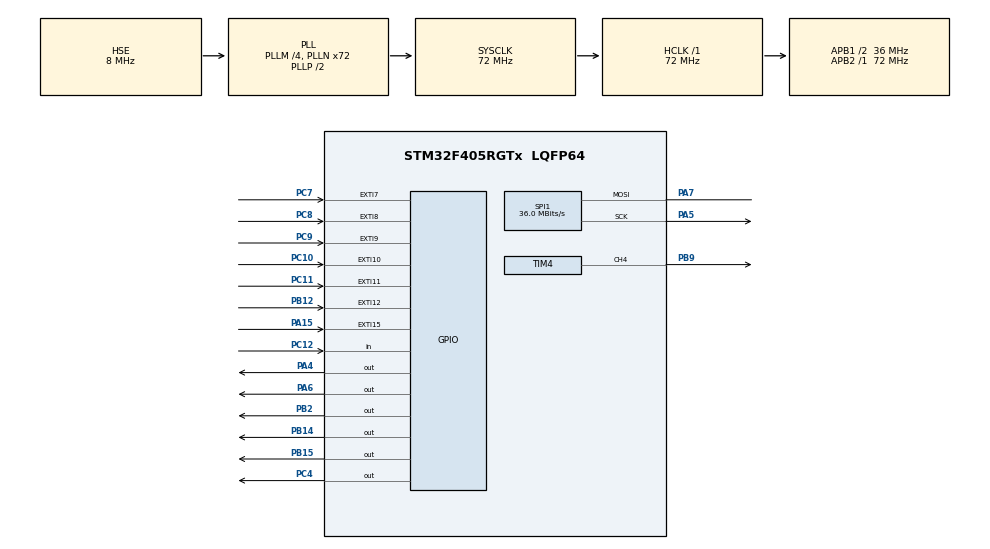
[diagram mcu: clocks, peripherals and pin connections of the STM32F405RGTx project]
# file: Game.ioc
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Dma.Request0=TIM4_UP
Dma.TIM4_UP.0.Direction=DMA_MEMORY_TO_PERIPH
Dma.TIM4_UP.0.FIFOMode=DMA_FIFOMODE_DISABLE
Dma.TIM4_UP.0.Instance=DMA1_Stream6
Dma.TIM4_UP.0.MemDataAlignment=DMA_MDATAALIGN_HALFWORD
Dma.TIM4_UP.0.MemInc=DMA_MINC_ENABLE
Dma.TIM4_UP.0.Mode=DMA_NORMAL
Dma.TIM4_UP.0.PeriphDataAlignment=DMA_PDATAALIGN_HALFWORD
Dma.TIM4_UP.0.PeriphInc=DMA_PINC_DISABLE
Dma.TIM4_UP.0.Priority=DMA_PRIORITY_LOW
Mcu.Family=STM32F4
Mcu.Name=STM32F405RGTx
Mcu.Package=LQFP64
NVIC.DMA1_Stream6_IRQn=true\:0\:0\:false\:false\:true\:false\:true
NVIC.EXTI15_10_IRQn=true\:0\:0\:false\:false\:true\:true\:true
NVIC.EXTI9_5_IRQn=true\:0\:0\:false\:false\:true\:true\:true
NVIC.HASH_RNG_IRQn=true\:0\:0\:false\:false\:true\:true\:true
NVIC.PriorityGroup=NVIC_PRIORITYGROUP_4
PA13.Mode=Serial_Wire
PA13.Signal=SYS_JTMS-SWDIO
PA14.Mode=Serial_Wire
PA14.Signal=SYS_JTCK-SWCLK
PA15.GPIO_ModeDefaultEXTI=GPIO_MODE_IT_RISING_FALLING
PA15.GPIO_PuPd=GPIO_PULLUP
PA15.Signal=GPXTI15
PA4.GPIO_PuPd=GPIO_PULLDOWN
PA4.PinState=GPIO_PIN_RESET
PA4.Signal=GPIO_Output
PA5.Mode=Simplex_Bidirectional_Master
PA5.Signal=SPI1_SCK
PA6.GPIO_PuPd=GPIO_PULLDOWN
PA6.Signal=GPIO_Output
PA7.Mode=Simplex_Bidirectional_Master
PA7.Signal=SPI1_MOSI
PB12.GPIO_PuPd=GPIO_PULLUP
PB12.Signal=GPXTI12
PB14.GPIO_PuPd=GPIO_PULLUP
PB14.Signal=GPIO_Output
PB15.GPIO_PuPd=GPIO_PULLUP
PB15.Signal=GPIO_Output
PB2.GPIO_PuPd=GPIO_PULLDOWN
PB2.Signal=GPIO_Output
PB9.Signal=S_TIM4_CH4
PC10.GPIO_ModeDefaultEXTI=GPIO_MODE_IT_RISING_FALLING
PC10.GPIO_PuPd=GPIO_PULLUP
PC10.Signal=GPXTI10
PC11.GPIO_ModeDefaultEXTI=GPIO_MODE_IT_RISING_FALLING
PC11.GPIO_PuPd=GPIO_PULLUP
PC11.Signal=GPXTI11
PC12.GPIO_PuPd=GPIO_PULLUP
PC12.Signal=GPIO_Input
PC4.GPIO_PuPd=GPIO_PULLDOWN
PC4.Signal=GPIO_Output
PC7.GPIO_ModeDefaultEXTI=GPIO_MODE_IT_RISING_FALLING
PC7.GPIO_PuPd=GPIO_PULLUP
PC7.Signal=GPXTI7
PC8.GPIO_ModeDefaultEXTI=GPIO_MODE_IT_RISING_FALLING
PC8.GPIO_PuPd=GPIO_PULLUP
PC8.Signal=GPXTI8
PC9.GPIO_ModeDefaultEXTI=GPIO_MODE_IT_RISING_FALLING
PC9.GPIO_PuPd=GPIO_PULLUP
PC9.Signal=GPXTI9
PH0-OSC_IN.Mode=HSE-External-Oscillator
PH0-OSC_IN.Signal=RCC_OSC_IN
PH1-OSC_OUT.Mode=HSE-External-Oscillator
PH1-OSC_OUT.Signal=RCC_OSC_OUT
ProjectManager.HeapSize=0x200
ProjectManager.StackSize=0x400
ProjectManager.TargetToolchain=STM32CubeIDE
RCC.48MHZClocksFreq_Value=36000000
RCC.AHBFreq_Value=72000000
RCC.APB1CLKDivider=RCC_HCLK_DIV2
RCC.APB1Freq_Value=36000000
RCC.APB1TimFreq_Value=72000000
RCC.APB2Freq_Value=72000000
RCC.APB2TimFreq_Value=72000000
RCC.CortexFreq_Value=72000000
RCC.HCLKFreq_Value=72000000
RCC.HSE_VALUE=8000000
RCC.HSI_VALUE=16000000
RCC.LSE_VALUE=32768
RCC.PLLM=4
RCC.PLLN=72
RCC.PLLSourceVirtual=RCC_PLLSOURCE_HSE
RCC.SYSCLKFreq_VALUE=72000000
RCC.SYSCLKSource=RCC_SYSCLKSOURCE_PLLCLK
RCC.VCOOutputFreq_Value=144000000
SH.S_TIM4_CH4.0=TIM4_CH4,PWM Generation4 CH4
SPI1.BaudRatePrescaler=SPI_BAUDRATEPRESCALER_2
SPI1.CalculateBaudRate=36.0 MBits/s
SPI1.Direction=SPI_DIRECTION_1LINE
SPI1.Mode=SPI_MODE_MASTER
SPI1.VirtualType=VM_MASTER
TIM4.AutoReloadPreload=TIM_AUTORELOAD_PRELOAD_DISABLE
TIM4.Channel-PWM\ Generation4\ CH4=TIM_CHANNEL_4
TIM4.Period=60000
TIM4.Prescaler=72-1
VP_RNG_VS_RNG.Mode=RNG_Activate
VP_TIM4_VS_ClockSourceINT.Mode=Internal
board=custom

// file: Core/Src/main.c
/* USER CODE BEGIN Header */
/**
  ******************************************************************************
  * @file           : main.c
  * @brief          : Main program body
  ******************************************************************************
  * @attention
  *
  * <h2><center>&copy; Copyright (c) 2022 STMicroelectronics.
  * All rights reserved.</center></h2>
  *
  * This software component is licensed by ST under BSD 3-Clause license,
  * the "License"; You may not use this file except in compliance with the
  * License. You may obtain a copy of the License at:
  *                        opensource.org/licenses/BSD-3-Clause
  *
  ******************************************************************************
  */
/* USER CODE END Header */
#include "main.h"
#include "dma.h"
#include "rng.h"
#include "spi.h"
#include "tim.h"
#include "gpio.h"

/* USER CODE BEGIN Includes */
#include "ssd1306.h"
#include "button.h"
#include "MicroMenu.h"
//#include "menu.h"
/* USER CODE END Includes */

/* USER CODE BEGIN PV */
//#include "Game_1.h"
/* USER CODE END PV */

void SystemClock_Config(void);

/* USER CODE BEGIN 0 */

/*** DUMY CODE ***/

/*** END DUMY CODE ***/

/* USER CODE END 0 */

int main(void)
{

  /* MCU Configuration--------------------------------------------------------*/

  /* Reset of all peripherals, Initializes the Flash interface and the Systick. */
  HAL_Init();

  /* Configure the system clock */
  SystemClock_Config();

  /* Initialize all configured peripherals */
  MX_GPIO_Init();
  MX_DMA_Init();
  MX_SPI1_Init();
  MX_RNG_Init();
  MX_TIM4_Init();
  /* USER CODE BEGIN 2 */
  //uint8_t a=0;
  //uint32_t osc = HAL_RCC_GetSysClockFreq();
  ssd1306_Init();
  HAL_TIM_PWM_Start(&htim4, TIM_CHANNEL_4);

	/* Set up the default menu text write callback, and navigate to an absolute menu item entry. */
	//Menu_SetGenericWriteCallback(Generic_Write);
	//Menu_Navigate(&Menu_1);

  /* USER CODE END 2 */

  /* Infinite loop */
  /* USER CODE BEGIN WHILE */
  while (1)
  {
	 Menu_General();

	//updateGame();
    //play_melody();

/*
	if (button_struct.btn_B == PRESSED_LONG){
		//ssd1306_Fill(Black);
		ssd1306_DrawRectangle(10, 40 ,SSD1306_WIDTH-1 - 9,SSD1306_HEIGHT-1 - 40,White); //(x1,y1,x2,y1,color);
		//for (uint8_t a=0; a<110; a=a+11){
			if ((button_struct.counters_btn[1] % 150) == 0){
				for (uint8_t i=0+a; i<10+a; i++) {
					for (uint8_t j=0; j<14; j++) {
						ssd1306_DrawPixel(12+i,25+j, White);
					}
				}
				ssd1306_UpdateScreen();
				if ( a<110) a=a+11;
				if (a == 110) a =0;
			}
		//}
		//ssd1306_UpdateScreen();
	}
	else {
//		ssd1306_Fill(Black);
//		ssd1306_UpdateScreen();
		a =0;
	}
*/
    /* USER CODE END WHILE */

  }
}

void SystemClock_Config(void)
{
  RCC_OscInitTypeDef RCC_OscInitStruct = {0};
  RCC_ClkInitTypeDef RCC_ClkInitStruct = {0};

  /** Configure the main internal regulator output voltage
  */
  __HAL_RCC_PWR_CLK_ENABLE();
  __HAL_PWR_VOLTAGESCALING_CONFIG(PWR_REGULATOR_VOLTAGE_SCALE1);
  /** Initializes the RCC Oscillators according to the specified parameters
  * in the RCC_OscInitTypeDef structure.
  */
  RCC_OscInitStruct.OscillatorType = RCC_OSCILLATORTYPE_HSE;
  RCC_OscInitStruct.HSEState = RCC_HSE_ON;
  RCC_OscInitStruct.PLL.PLLState = RCC_PLL_ON;
  RCC_OscInitStruct.PLL.PLLSource = RCC_PLLSOURCE_HSE;
  RCC_OscInitStruct.PLL.PLLM = 4;
  RCC_OscInitStruct.PLL.PLLN = 72;
  RCC_OscInitStruct.PLL.PLLP = RCC_PLLP_DIV2;
  RCC_OscInitStruct.PLL.PLLQ = 4;
  if (HAL_RCC_OscConfig(&RCC_OscInitStruct) != HAL_OK)
  {
    Error_Handler();
  }
  /** Initializes the CPU, AHB and APB buses clocks
  */
  RCC_ClkInitStruct.ClockType = RCC_CLOCKTYPE_HCLK|RCC_CLOCKTYPE_SYSCLK
                              |RCC_CLOCKTYPE_PCLK1|RCC_CLOCKTYPE_PCLK2;
  RCC_ClkInitStruct.SYSCLKSource = RCC_SYSCLKSOURCE_PLLCLK;
  RCC_ClkInitStruct.AHBCLKDivider = RCC_SYSCLK_DIV1;
  RCC_ClkInitStruct.APB1CLKDivider = RCC_HCLK_DIV2;
  RCC_ClkInitStruct.APB2CLKDivider = RCC_HCLK_DIV1;

  if (HAL_RCC_ClockConfig(&RCC_ClkInitStruct, FLASH_LATENCY_2) != HAL_OK)
  {
    Error_Handler();
  }
}

void Error_Handler(void)
{
  __disable_irq();
  while (1)
  {
  }
}

/************************ (C) COPYRIGHT STMicroelectronics *****END OF FILE****/
